# AVR32DD20 register map
Vendor: Atmel; File version: 1.0
CPU: other r0p0, little endian, no MPU, no FPU, 4 interrupt priority bits
Registers are 8-bit, read-write, reset 0x0 unless marked. A register's access mark holds for its fields unless they carry their own. Offsets are from the block's base; lines under a group give offsets from that group; [hi:lo] are bit positions; {n}, {i} and the like mark numbered series; 'fields as' and 'values as' point back to an identical list; <NAME> marks a mode.

## Memory map
0x00000000 VPORTA size 0x4 — Virtual Ports
0x00000008 VPORTC size 0x4 — Virtual Ports
0x0000000C VPORTD size 0x4 — Virtual Ports
0x00000014 VPORTF size 0x4 — Virtual Ports
0x0000001C GPR size 0x4 — General Purpose Registers
0x00000034 CPU size 0x1
0x00000040 RSTCTRL size 0x2 — Reset controller
0x00000050 SLPCTRL size 0x2 — Sleep Controller
0x00000060 CLKCTRL blocks up to offset 0x21 — Clock controller
0x000000A0 BOD blocks up to offset 0xC — Bod interface
0x000000B0 VREF blocks up to offset 0x5 — Voltage reference
0x000000C0 MVIO size 0x3 — Multi-Voltage I/O
0x00000100 WDT size 0x2 — Watch-Dog Timer
0x00000110 CPUINT size 0x4 — Interrupt Controller
0x00000120 CRCSCAN size 0x3
0x00000140 RTC blocks up to offset 0x16 — Real-Time Counter
0x000001C0 CCL blocks up to offset 0x18 — Configurable Custom Logic
0x00000200 EVSYS blocks up to offset 0x39 — Event System
0x00000400 PORTA blocks up to offset 0x18 — I/O Ports
0x00000440 PORTC blocks up to offset 0x18 — I/O Ports
0x00000460 PORTD blocks up to offset 0x18 — I/O Ports
0x000004A0 PORTF blocks up to offset 0x18 — I/O Ports
0x000005E0 PORTMUX blocks up to offset 0xA — Port Multiplexer
0x00000600 ADC0 blocks up to offset 0x16 — Analog to Digital Converter
0x00000680 AC0 blocks up to offset 0x8 — Analog Comparator
0x000006A0 DAC0 blocks up to offset 0x4 — Digital to Analog Converter
0x000006D8 ZCD3 blocks up to offset 0x4 — Zero Cross Detect
0x00000800 USART0 size 0xF — Universal Synchronous and Asynchronous Receiver and Transmitter
0x00000820 USART1 size 0xF — Universal Synchronous and Asynchronous Receiver and Transmitter
0x00000900 TWI0 size 0xF — Two-Wire Interface
0x00000940 SPI0 size 0x5 — Serial Peripheral Interface
0x00000A00 TCA0 blocks up to offset 0x3E — 16-bit Timer/Counter Type A
0x00000B00 TCB0 blocks up to offset 0xE — 16-bit Timer Type B
0x00000B10 TCB1 blocks up to offset 0xE — 16-bit Timer Type B
0x00000B80 TCD0 blocks up to offset 0x30 — Timer Counter D
0x00000F01 SYSCFG blocks up to offset 0x5 — System Configuration Registers
0x00001000 NVMCTRL blocks up to offset 0xC — Non-volatile Memory Controller
0x00001040 LOCK size 0x4 — Lockbits
0x00001050 FUSE blocks up to offset 0x9 — Fuses
0x00001080 USERROW size 0x20
0x00001100 SIGROW blocks up to offset 0x20 — Signature row

## Interrupts
1 CRCSCAN_NMI (CPU)
2 BOD_VLM (CPU)
3 CLKCTRL_CFD (CPU)
4 MVIO_MVIO (CPU)
5 RTC_CNT (CPU)
6 RTC_PIT (CPU)
7 CCL_CCL (CPU)
8 PORTA_PORT (CPU)
9 TCA0_LUNF_OVF (CPU)
10 TCA0_HUNF (CPU)
11 TCA0_CMP0_LCMP0 (CPU)
12 TCA0_CMP1_LCMP1 (CPU)
13 TCA0_CMP2_LCMP2 (CPU)
14 TCB0_INT (CPU)
15 TCB1_INT (CPU)
16 TCD0_OVF (CPU)
17 TCD0_TRIG (CPU)
18 TWI0_TWIS (CPU)
19 TWI0_TWIM (CPU)
20 SPI0_INT (CPU)
21 USART0_RXC (CPU)
22 USART0_DRE (CPU)
23 USART0_TXC (CPU)
24 PORTD_PORT (CPU)
25 AC0_AC (CPU)
26 ADC0_RESRDY (CPU)
27 ADC0_WCMP (CPU)
28 ZCD3_ZCD (CPU)
29 PORTC_PORT (CPU)
31 USART1_RXC (CPU)
32 USART1_DRE (CPU)
33 USART1_TXC (CPU)
34 PORTF_PORT (CPU)
35 NVMCTRL_EE (CPU)

## AC0 — Analog Comparator
Base 0x00000680
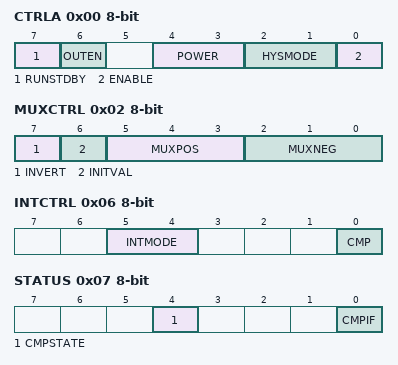
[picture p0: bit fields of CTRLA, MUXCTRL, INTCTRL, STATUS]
0x00 CTRLA — Control A
  [7] RUNSTDBY — Run in Standby Mode
  [6] OUTEN — Output Pad Enable
  [4:3] POWER — Power profile
    0=PROFILE0 (Power profile 0, Shortest response time, highest consumption); 1=PROFILE1 (Power profile 1); 2=PROFILE2 (Power profile 2); 3=PROFILE3 (Power profile 3)
  [2:1] HYSMODE — Hysteresis Mode
    0=NONE (No hysteresis); 1=SMALL (Small hysteresis); 2=MEDIUM (Medium hysteresis); 3=LARGE (Large hysteresis)
  [0] ENABLE
0x02 MUXCTRL — Mux Control A
  [7] INVERT — Invert AC Output
  [6] INITVAL — AC Output Initial Value
    0=LOW (Output initialized to 0); 1=HIGH (Output initialized to 1)
  [5:3] MUXPOS — Positive Input MUX Selection
    0=AINP0 (Positive Pin 0); 3=AINP3 (Positive Pin 3); 4=AINP4 (Positive Pin 4)
  [2:0] MUXNEG — Negative Input MUX Selection
    0=AINN0 (Negative Pin 0); 2=AINN2 (Negative Pin 2); 3=AINN3 (Negative Pin 3); 4=DACREF (DAC Reference)
0x05 DACREF — DAC Voltage Reference
0x06 INTCTRL — Interrupt Control
  [5:4] INTMODE — Interrupt Mode
    0=BOTHEDGE (Positive and negative inputs crosses); 2=NEGEDGE (Positive input goes below negative input); 3=POSEDGE (Positive input goes above negative input)
  [0] CMP — Interrupt Enable
0x07 STATUS
  [4] CMPSTATE ro — Analog Comparator State
  [0] CMPIF — Analog Comparator Interrupt Flag
